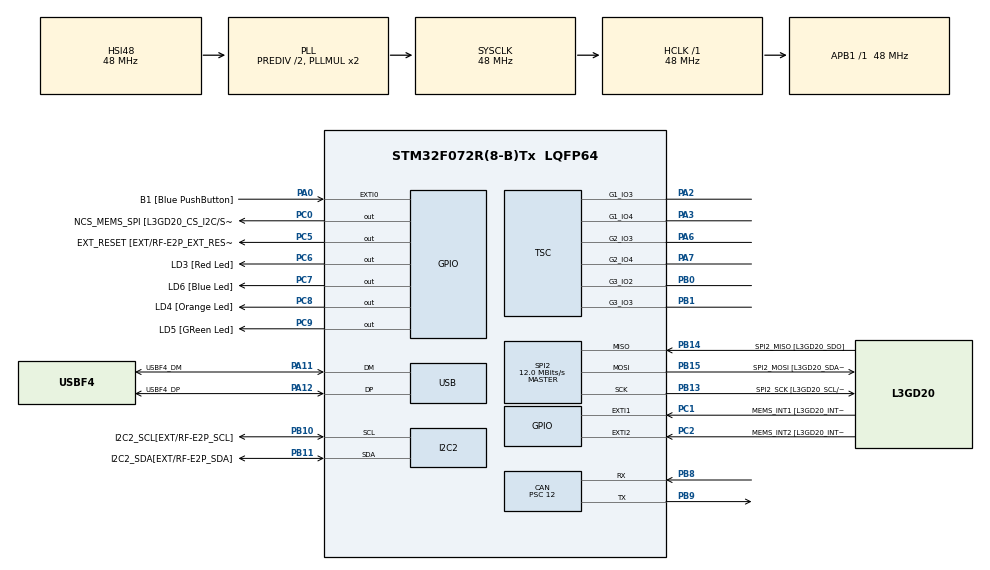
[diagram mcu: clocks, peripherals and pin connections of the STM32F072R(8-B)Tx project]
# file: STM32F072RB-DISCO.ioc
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CAN.ABOM=ENABLE
CAN.AWUM=ENABLE
CAN.BS1=CAN_BS1_13TQ
CAN.BS2=CAN_BS2_2TQ
CAN.CalculateBaudRate=250000
CAN.CalculateTimeBit=4000
CAN.CalculateTimeQuantum=250.0
CAN.NART=ENABLE
CAN.Prescaler=12
I2C2.Timing=0x20303E5D
Mcu.Family=STM32F0
Mcu.Name=STM32F072R(8-B)Tx
Mcu.Package=LQFP64
NVIC.CEC_CAN_IRQn=true\:1\:0\:true\:false\:true\:true\:true\:true
NVIC.TIM14_IRQn=true\:2\:0\:true\:false\:true\:true\:true\:true
NVIC.TIM17_IRQn=true\:3\:0\:false\:false\:true\:false\:true\:true
NVIC.TimeBase=TIM17_IRQn
NVIC.TimeBaseIP=TIM17
NVIC.USB_IRQn=true\:2\:0\:true\:false\:true\:true\:true\:true
PA0.GPIO_Label=B1 [Blue PushButton]
PA0.GPIO_ModeDefaultEXTI=GPIO_MODE_EVT_RISING
PA0.Signal=GPXTI0
PA11.GPIO_Label=USBF4_DM
PA11.Mode=Device
PA11.Signal=USB_DM
PA12.GPIO_Label=USBF4_DP
PA12.Mode=Device
PA12.Signal=USB_DP
PA13.GPIO_Label=SWDIO
PA13.Mode=Serial_Wire
PA13.Signal=SYS_SWDIO
PA14.GPIO_Label=SWCLK
PA14.Mode=Serial_Wire
PA14.Signal=SYS_SWCLK
PA2.Mode=G1_IO3-Channel
PA2.Signal=TSC_G1_IO3
PA3.Mode=G1_IO4-Sampling
PA3.Signal=TSC_G1_IO4
PA6.Mode=G2_IO3-Channel
PA6.Signal=TSC_G2_IO3
PA7.Mode=G2_IO4-Sampling
PA7.Signal=TSC_G2_IO4
PB0.Mode=G3_IO2-Channel
PB0.Signal=TSC_G3_IO2
PB1.Mode=G3_IO3-Sampling
PB1.Signal=TSC_G3_IO3
PB10.GPIO_Label=I2C2_SCL[EXT/RF-E2P_SCL]
PB10.GPIO_Pu=GPIO_PULLUP
PB10.Mode=I2C
PB10.Signal=I2C2_SCL
PB11.GPIO_Label=I2C2_SDA[EXT/RF-E2P_SDA]
PB11.GPIO_Pu=GPIO_PULLUP
PB11.Mode=I2C
PB11.Signal=I2C2_SDA
PB13.GPIO_Label=SPI2_SCK [L3GD20_SCL/SPC]
PB13.Mode=Full_Duplex_Master
PB13.Signal=SPI2_SCK
PB14.GPIO_Label=SPI2_MISO [L3GD20_SDO]
PB14.Mode=Full_Duplex_Master
PB14.Signal=SPI2_MISO
PB15.GPIO_Label=SPI2_MOSI [L3GD20_SDA/SDI]
PB15.Mode=Full_Duplex_Master
PB15.Signal=SPI2_MOSI
PB8.GPIO_FM8=SYSCFG_CFGR1_I2C_FMP_PB8
PB8.Mode=CAN_Activate
PB8.Signal=CAN_RX
PB9.GPIO_FM9=SYSCFG_CFGR1_I2C_FMP_PB9
PB9.Mode=CAN_Activate
PB9.Signal=CAN_TX
PC0.GPIO_Label=NCS_MEMS_SPI [L3GD20_CS_I2C/SPI]
PC0.Signal=GPIO_Output
PC1.GPIO_Label=MEMS_INT1 [L3GD20_INT1]
PC1.GPIO_ModeDefaultEXTI=GPIO_MODE_EVT_RISING
PC1.Signal=GPXTI1
PC2.GPIO_Label=MEMS_INT2 [L3GD20_INT2]
PC2.GPIO_ModeDefaultEXTI=GPIO_MODE_EVT_RISING
PC2.Signal=GPXTI2
PC5.GPIO_Label=EXT_RESET [EXT/RF-E2P_EXT_RESET]
PC5.Signal=GPIO_Output
PC6.GPIO_Label=LD3 [Red Led]
PC6.Signal=GPIO_Output
PC7.GPIO_Label=LD6 [Blue Led]
PC7.Signal=GPIO_Output
PC8.GPIO_Label=LD4 [Orange Led]
PC8.Signal=GPIO_Output
PC9.GPIO_Label=LD5 [GReen Led]
PC9.Signal=GPIO_Output
ProjectManager.HeapSize=0x200
ProjectManager.StackSize=0x400
ProjectManager.TargetToolchain=Makefile
RCC.AHBFreq_Value=48000000
RCC.APB1Freq_Value=48000000
RCC.APB1TimFreq_Value=48000000
RCC.HCLKFreq_Value=48000000
RCC.LockedElements=APB1Output,TimPrescOut1,FCLKCortexOutput,HCLKOutput,AHBOutput
RCC.PLLDivider=RCC_PREDIV_DIV2
RCC.PLLSourceVirtual=RCC_PLLSOURCE_HSI48
RCC.SYSCLKFreq_VALUE=48000000
RCC.SYSCLKSource=RCC_SYSCLKSOURCE_PLLCLK
SPI2.BaudRatePrescaler=SPI_BAUDRATEPRESCALER_4
SPI2.CalculateBaudRate=12.0 MBits/s
SPI2.Direction=SPI_DIRECTION_2LINES
SPI2.Mode=SPI_MODE_MASTER
SPI2.VirtualType=VM_MASTER
TIM14.Period=99
TIM14.Prescaler=47
USB.phy_itface=PCD_PHY_EMBEDDED
USB.speed=PCD_SPEED_FULL
VP_SYS_VS_tim17.Mode=TIM17
VP_TIM14_VS_ClockSourceINT.Mode=Enable_Timer
board=STM32F072B-DISCO

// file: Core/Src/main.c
/* USER CODE BEGIN Header */
/**
  ******************************************************************************
  * @file           : main.c
  * @brief          : Main program body
  ******************************************************************************
  * @attention
  *
  * Copyright (c) 2023 STMicroelectronics.
  * All rights reserved.
  *
  * This software is licensed under terms that can be found in the LICENSE file
  * in the root directory of this software component.
  * If no LICENSE file comes with this software, it is provided AS-IS.
  *
  ******************************************************************************
  */
/* USER CODE END Header */
#include "main.h"
#include "can.h"
#include "i2c.h"
#include "spi.h"
#include "tim.h"
#include "tsc.h"
#include "usb.h"
#include "gpio.h"

/* USER CODE BEGIN Includes */
extern void app_main(void);
__weak void Timer14UpdateCallback(void)
{
  /* Do nothing */
}
/* USER CODE END Includes */

void SystemClock_Config(void);

int main(void)
{

  /* MCU Configuration--------------------------------------------------------*/

  /* Reset of all peripherals, Initializes the Flash interface and the Systick. */
  HAL_Init();

  /* Configure the system clock */
  SystemClock_Config();

  /* Initialize all configured peripherals */
  MX_GPIO_Init();
  MX_CAN_Init();
  MX_I2C2_Init();
  MX_SPI2_Init();
  MX_TSC_Init();
  MX_USB_PCD_Init();
  MX_TIM14_Init();
  /* USER CODE BEGIN 2 */
  app_main();
  /* USER CODE END 2 */

  /* Infinite loop */
  while (1)
  {

  }
}

void SystemClock_Config(void)
{
  RCC_OscInitTypeDef RCC_OscInitStruct = {0};
  RCC_ClkInitTypeDef RCC_ClkInitStruct = {0};
  RCC_PeriphCLKInitTypeDef PeriphClkInit = {0};

  /** Initializes the RCC Oscillators according to the specified parameters
  * in the RCC_OscInitTypeDef structure.
  */
  RCC_OscInitStruct.OscillatorType = RCC_OSCILLATORTYPE_HSI48;
  RCC_OscInitStruct.HSI48State = RCC_HSI48_ON;
  RCC_OscInitStruct.PLL.PLLState = RCC_PLL_ON;
  RCC_OscInitStruct.PLL.PLLSource = RCC_PLLSOURCE_HSI48;
  RCC_OscInitStruct.PLL.PLLMUL = RCC_PLL_MUL2;
  RCC_OscInitStruct.PLL.PREDIV = RCC_PREDIV_DIV2;
  if (HAL_RCC_OscConfig(&RCC_OscInitStruct) != HAL_OK)
  {
    Error_Handler();
  }

  /** Initializes the CPU, AHB and APB buses clocks
  */
  RCC_ClkInitStruct.ClockType = RCC_CLOCKTYPE_HCLK|RCC_CLOCKTYPE_SYSCLK
                              |RCC_CLOCKTYPE_PCLK1;
  RCC_ClkInitStruct.SYSCLKSource = RCC_SYSCLKSOURCE_PLLCLK;
  RCC_ClkInitStruct.AHBCLKDivider = RCC_SYSCLK_DIV1;
  RCC_ClkInitStruct.APB1CLKDivider = RCC_HCLK_DIV1;

  if (HAL_RCC_ClockConfig(&RCC_ClkInitStruct, FLASH_LATENCY_1) != HAL_OK)
  {
    Error_Handler();
  }
  PeriphClkInit.PeriphClockSelection = RCC_PERIPHCLK_USB;
  PeriphClkInit.UsbClockSelection = RCC_USBCLKSOURCE_HSI48;

  if (HAL_RCCEx_PeriphCLKConfig(&PeriphClkInit) != HAL_OK)
  {
    Error_Handler();
  }
}

void HAL_TIM_PeriodElapsedCallback(TIM_HandleTypeDef *htim)
{
  if (htim->Instance == TIM17) {
    HAL_IncTick();
  }
  /* USER CODE BEGIN Callback 1 */
  if (htim->Instance == TIM14) {
    Timer14UpdateCallback();
  }
  /* USER CODE END Callback 1 */
}

void Error_Handler(void)
{
  __disable_irq();
  while (1)
  {
  }
}
